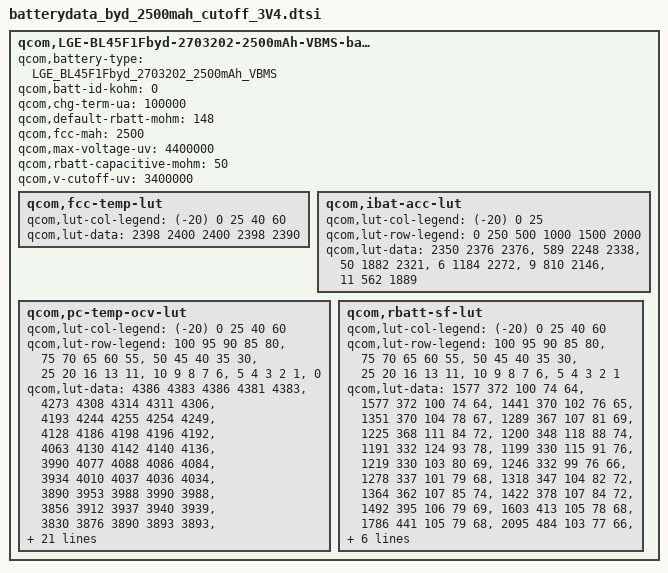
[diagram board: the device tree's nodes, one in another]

qcom,LGE-BL45F1Fbyd-2703202-2500mAh-VBMS-batterydata {
	qcom,battery-type = "LGE_BL45F1Fbyd_2703202_2500mAh_VBMS";
	qcom,batt-id-kohm = <0>;
	qcom,chg-term-ua = <100000>;
	qcom,default-rbatt-mohm = <148>;
	qcom,fcc-mah = <2500>;
	qcom,max-voltage-uv = <4400000>;
	qcom,rbatt-capacitive-mohm = <50>;
	qcom,v-cutoff-uv = <3400000>;

	qcom,fcc-temp-lut {
		qcom,lut-col-legend = <(-20) 0 25 40 60>;
		qcom,lut-data = <2398 2400 2400 2398 2390>;
	};

	qcom,ibat-acc-lut {
		qcom,lut-col-legend = <(-20) 0 25>;
		qcom,lut-row-legend = <0 250 500 1000 1500 2000>;
		qcom,lut-data = <2350 2376 2376>,
				<589 2248 2338>,
				<50 1882 2321>,
				<6 1184 2272>,
				<9 810 2146>,
				<11 562 1889>;
	};

	qcom,pc-temp-ocv-lut {
		qcom,lut-col-legend = <(-20) 0 25 40 60>;
		qcom,lut-row-legend = <100 95 90 85 80>,
					<75 70 65 60 55>,
					<50 45 40 35 30>,
					<25 20 16 13 11>,
					<10 9 8 7 6>,
					<5 4 3 2 1>,
					<0>;
		qcom,lut-data = <4386 4383 4386 4381 4383>,
				<4273 4308 4314 4311 4306>,
				<4193 4244 4255 4254 4249>,
				<4128 4186 4198 4196 4192>,
				<4063 4130 4142 4140 4136>,
				<3990 4077 4088 4086 4084>,
				<3934 4010 4037 4036 4034>,
				<3890 3953 3988 3990 3988>,
				<3856 3912 3937 3940 3939>,
				<3830 3876 3890 3893 3893>,
				<3808 3844 3856 3858 3858>,
				<3790 3816 3830 3832 3832>,
				<3774 3795 3808 3810 3810>,
				<3758 3780 3790 3792 3790>,
				<3745 3767 3773 3772 3767>,
				<3730 3752 3756 3750 3739>,
				<3714 3730 3736 3728 3716>,
				<3698 3714 3716 3708 3695>,
				<3682 3704 3696 3689 3678>,
				<3666 3697 3690 3683 3672>,
				<3658 3693 3688 3682 3670>,
				<3649 3689 3686 3680 3669>,
				<3638 3684 3684 3679 3666>,
				<3624 3678 3682 3676 3662>,
				<3606 3668 3674 3666 3648>,
				<3583 3648 3652 3641 3617>,
				<3552 3613 3610 3597 3570>,
				<3506 3560 3553 3538 3508>,
				<3436 3486 3474 3458 3430>,
				<3318 3367 3356 3335 3303>,
				<3000 3000 3000 3000 3000>;
	};

	qcom,rbatt-sf-lut {
		qcom,lut-col-legend = <(-20) 0 25 40 60>;
		qcom,lut-row-legend = <100 95 90 85 80>,
					<75 70 65 60 55>,
					<50 45 40 35 30>,
					<25 20 16 13 11>,
					<10 9 8 7 6>,
					<5 4 3 2 1>;
		qcom,lut-data = <1577 372 100 74 64>,
				<1577 372 100 74 64>,
				<1441 370 102 76 65>,
				<1351 370 104 78 67>,
				<1289 367 107 81 69>,
				<1225 368 111 84 72>,
				<1200 348 118 88 74>,
				<1191 332 124 93 78>,
				<1199 330 115 91 76>,
				<1219 330 103 80 69>,
				<1246 332 99 76 66>,
				<1278 337 101 79 68>,
				<1318 347 104 82 72>,
				<1364 362 107 85 74>,
				<1422 378 107 84 72>,
				<1492 395 106 79 69>,
				<1603 413 105 78 68>,
				<1786 441 105 79 68>,
				<2095 484 103 77 66>,
				<2389 525 105 78 68>,
				<2558 549 108 81 70>,
				<2752 573 111 83 72>,
				<2972 599 115 86 74>,
				<3136 610 120 89 77>,
				<3290 597 122 89 74>,
				<3819 626 118 84 70>,
				<4651 670 114 82 70>,
				<5896 745 118 84 74>,
				<8036 868 128 93 82>,
				<14568 1257 166 132 126>;
	};
};
